# BlueNRG_LP register map
File version: 1.0
CPU: CM0+ r0p0, little endian, no MPU, no FPU, 2 interrupt priority bits
Registers are 32-bit, read-write, reset 0x0 unless marked. A register's access mark holds for its fields unless they carry their own. Offsets are from the block's base; [hi:lo] are bit positions; {n}, {i} and the like mark numbered series.

## ADC
Base 0x41006000
0x00 VERSION_ID ro reset 0x20
  [7:0] VERSION_ID — version of the embedded IP.
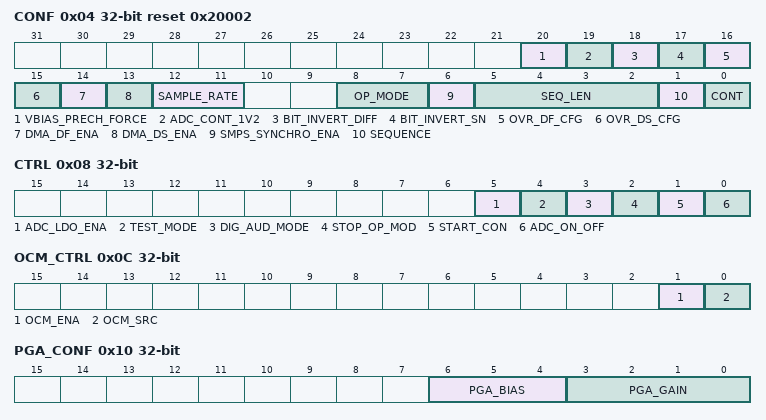
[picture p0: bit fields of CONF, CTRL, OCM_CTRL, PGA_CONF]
0x04 CONF reset 0x20002 — ADC configuration register
  [20] VBIAS_PRECH_FORCE — possibility to keep the VBIAS_PRECH enabled to deactivate the filter
  [19] ADC_CONT_1V2 — select the input sampling method
  [18] BIT_INVERT_DIFF — invert bit to bit the ADC data output when a differential
  [17] BIT_INVERT_SN — invert bit to bit the ADC data output when a single
  [16] OVR_DF_CFG — decimation overrun configuration
  [15] OVR_DS_CFG — Down Sampler overrun configuration
  [14] DMA_DF_ENA — enable DMA mode for Decimation Filter data path
  [13] DMA_DS_ENA — enable DMA mode for Down Sampler data path
  [12:11] SAMPLE_RATE — conversion rate of ADC
  [8:7] OP_MODE — ADC mode selection (= data path selection)
  [6] SMPS_SYNCHRO_ENA — synchronize the ADC start conversion with a pulse generated by the
  [5:2] SEQ_LEN — number of conversions in a regular sequence
  [1] SEQUENCE — enable the sequence mode (active by default)
  [0] CONT — regular sequence runs continuously when ADC mode is enabled
0x08 CTRL — ADC control register
  [5] ADC_LDO_ENA — enable the LDO associated to the ADC block
  [4] TEST_MODE — select the functional or the test mode of the ADC
  [3] DIG_AUD_MODE — enable the digital audio mode (the data path uses the decimation filter)
  [2] STOP_OP_MOD — stop the on-going OP_MODE (ADC mode, Analog audio mode, Full
  [1] START_CON — generate a start pulse to initiate an ADC conversion
  [0] ADC_ON_OFF
0x0C OCM_CTRL — Occasionnal mode control register
  [1] OCM_ENA — start occasional conversion in analog audio and full modes
  [0] OCM_SRC — select the occasional conversion source
0x10 PGA_CONF — PGA configuration register
  [6:4] PGA_BIAS — set the microphone bias voltage
  [3:0] PGA_GAIN — from 6 to 30 dB
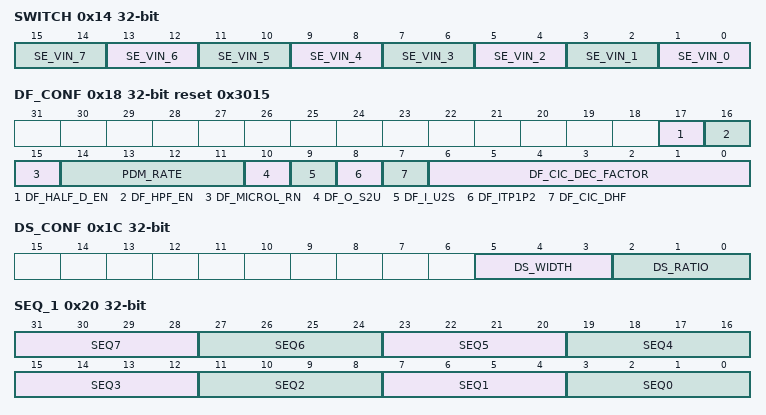
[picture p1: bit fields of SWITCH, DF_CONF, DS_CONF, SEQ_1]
0x14 SWITCH — ADC switch control for Input Selection
  [2n+1:2n] SE_VIN_{n} (n=4..7) — input voltage for VINP[{n-4}]
  [2n+1:2n] SE_VIN_{n} (n=0..3) — input voltage for VINM[{n}] / VINP[{n}]-VINM[{n}]
0x18 DF_CONF reset 0x3015 — Decimation filter configuration register
  [17] DF_HALF_D_EN — half dynamic enable.
  [16] DF_HPF_EN — high pass filter enable.
  [15] DF_MICROL_RN — left/right channel selection on digital microphone
  [14:11] PDM_RATE — select the PDM clock rate.
  [10] DF_O_S2U — select signed/unsigned format for data output
  [9] DF_I_U2S — select signed/unsigned format for input
  [8] DF_ITP1P2 — 1.2 fractional interpolator enable
  [7] DF_CIC_DHF — CIC filter decimator half factor
  [6:0] DF_CIC_DEC_FACTOR
0x1C DS_CONF — Downsampler configuration register
  [5:3] DS_WIDTH — program the Down Sampler width of data output (DSDTATA)
  [2:0] DS_RATIO — program the Down Sampler ratio (N factor)
0x20 SEQ_1 — ADC regular sequence configuration register 1
  [4n+3:4n] SEQ{n} (n=3..7) — channel number code for {n+1}th conversion of the sequence.
  [11:8] SEQ2 — channel number code for 3rd conversion of the sequence.
  [7:4] SEQ1 — channel number code for second conversion of the sequence.
  [3:0] SEQ0 — channel number code for first conversion of the sequence
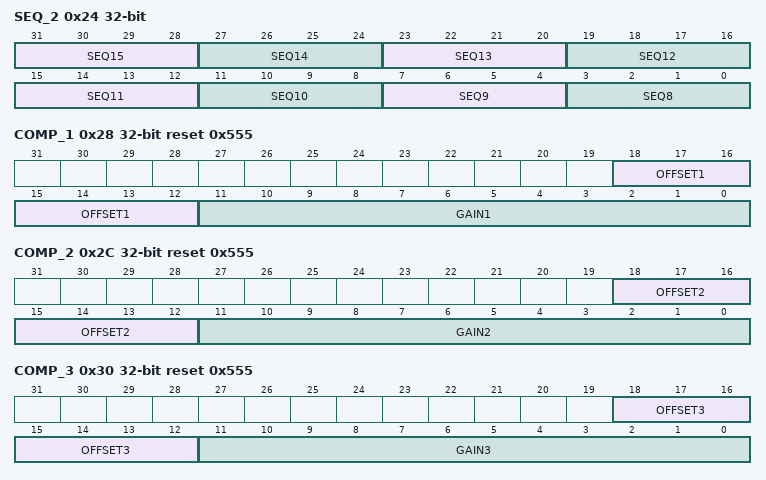
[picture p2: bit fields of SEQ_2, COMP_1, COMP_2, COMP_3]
0x24 SEQ_2 — ADC regular sequence configuration register 2
  [4n-29:4n-32] SEQ{n} (n=9..15) — channel number code for {n+1}th conversion of the sequence.
  [3:0] SEQ8 — channel number code for 9th conversion of the sequence
0x28 COMP_1 reset 0x555 — ADC Gain and offset correction values register 1
  [18:12] OFFSET1 — first calibration point: signed offset compensation[6:0]
  [11:0] GAIN1 — first calibration point: gain AUXADC_GAIN_1V2[11:0]
0x2C COMP_2 reset 0x555 — ADC Gain and offset correction values register 2
  [18:12] OFFSET2 — second calibration point: signed offset compensation[6:0]
  [11:0] GAIN2 — second calibration point: gain AUXADC_GAIN_1V2[11:0]
0x30 COMP_3 reset 0x555 — ADC Gain and offset correction values register 3
  [18:12] OFFSET3 — third calibration point: signed offset compensation[6:0]
  [11:0] GAIN3 — third calibration point: gain AUXADC_GAIN_1V2[11:0]
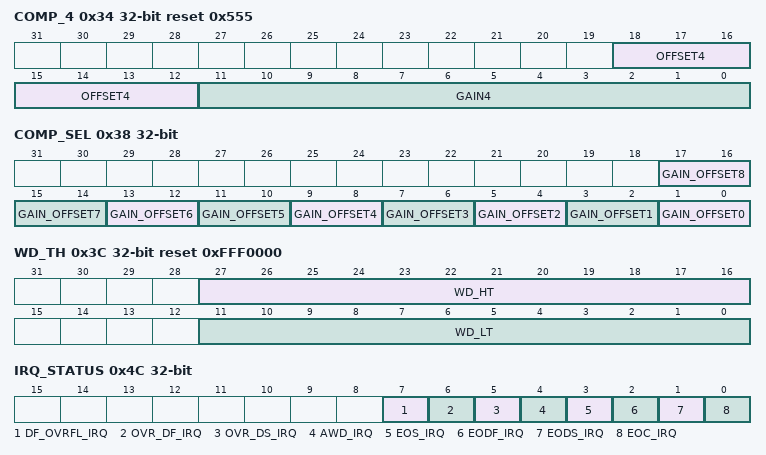
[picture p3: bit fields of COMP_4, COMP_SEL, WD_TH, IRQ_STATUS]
0x34 COMP_4 reset 0x555 — ADC Gain and offset correction values register 4
  [18:12] OFFSET4 — fourth calibration point: signed offset compensation[6:0]
  [11:0] GAIN4 — fourth calibration point: gain AUXADC_GAIN_1V2[11:0]
0x38 COMP_SEL — ADC Gain and Offset selection values register
  [17:16] GAIN_OFFSET8 — gain / offset used in ADC differential mode with Vinput range = 3.6V
  [15:14] GAIN_OFFSET7 — gain / offset used in ADC single positive mode with Vinput range = 3.6V
  [13:12] GAIN_OFFSET6 — gain / offset used in ADC single negative mode with Vinput range = 3.6V
  [11:10] GAIN_OFFSET5 — gain / offset used in ADC differential mode with Vinput range = 2.4V
  [9:8] GAIN_OFFSET4 — gain / offset used in ADC single positive mode with Vinput range = 2.4V
  [7:6] GAIN_OFFSET3 — gain / offset used in ADC single negative mode with Vinput range = 2.4V
  [5:4] GAIN_OFFSET2 — gain / offset used in ADC differential mode with Vinput range = 1.2V
  [3:2] GAIN_OFFSET1 — gain / offset used in ADC single positive mode with Vinput range = 1.2V
  [1:0] GAIN_OFFSET0 — gain / offset used in ADC single negative mode with Vinput range = 1.2V
0x3C WD_TH reset 0xFFF0000 — High/low limits for event monitoring a channel register
  [27:16] WD_HT — analog watchdog high level threshold.
  [11:0] WD_LT — analog watchdog low level threshold.
0x40 WD_CONF — Channel selection for event monitoring register
  [15:0] AWD_CHX — analog watchdog channel selection to define which input channel(s) need to be guarded by the watchdog.
0x44 DS_DATAOUT ro — Downsampler Data output register
  [15:0] DS_DATA — contain the converted data at the output of the Down Sampler.
0x48 DF_DATAOUT ro — Decimation filter Data output register
  [15:0] DF_DATA — contain the converted data at the output of the decimation filter.
0x4C IRQ_STATUS — Interrupt Status register
  [7] DF_OVRFL_IRQ — set to indicate the decimation filter is saturated.
  [6] OVR_DF_IRQ — set to indicate a decimation filter overrun (a data is lost)
  [5] OVR_DS_IRQ — set to indicate a Down Sampler overrun (at least one data is lost)
  [4] AWD_IRQ — set when an analog watchdog event occurs.
  [3] EOS_IRQ — set when a sequence of conversion is completed.
  [2] EODF_IRQ — set when the decimation filter conversion is completed.
  [1] EODS_IRQ — set when the Down Sampler conversion is completed.
  [0] EOC_IRQ — (Used in test mode only): set when the ADC conversion is completed.
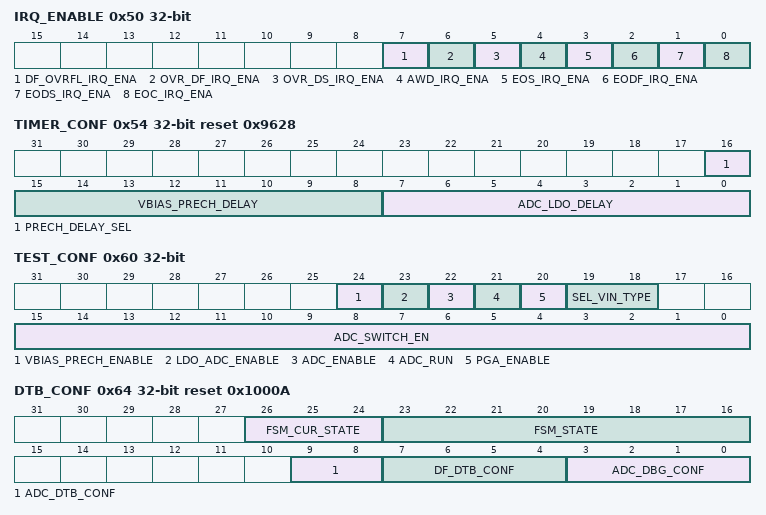
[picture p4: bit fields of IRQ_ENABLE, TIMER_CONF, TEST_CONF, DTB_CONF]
0x50 IRQ_ENABLE — Enable/disable Interrupts
  [7] DF_OVRFL_IRQ_ENA — decimation filter saturation interrupt enable
  [6] OVR_DF_IRQ_ENA — decimation filter overrun interrupt enable
  [5] OVR_DS_IRQ_ENA — Down Sampler overrun interrupt enable
  [4] AWD_IRQ_ENA — analog watchdog interrupt enable
  [3] EOS_IRQ_ENA — End of regular sequence interrupt enable
  [2] EODF_IRQ_ENA — End of conversion interrupt enable for the decimation filter output
  [1] EODS_IRQ_ENA — End of conversion interrupt enable for the Down Sampler output
  [0] EOC_IRQ_ENA — (Used in test mode only): End of ADC conversion interrupt enable
0x54 TIMER_CONF reset 0x9628 — Time to add after an LDO Enable or ADC Enable to let the HW to be stable before using it
  [16] PRECH_DELAY_SEL — Select the time step PD_STEP for the VBIAS_PRECH_DELAY timer.
  [15:8] VBIAS_PRECH_DELAY — define the duration of a waiting time starting at rising edge of PGA_EN signal and corresponding to the VBIAS precharge duration.
  [7:0] ADC_LDO_DELAY — define the duration of a waiting time to be inserted between the ADC_LDO enable and the ADC ON to let time to the LDO to stabilize before starting a conversion.
0x60 TEST_CONF
  [24] VBIAS_PRECH_ENABLE — set and reset by the software, knowing the bit must stay high at
  [23] LDO_ADC_ENABLE
  [22] ADC_ENABLE
  [21] ADC_RUN — Start/stop ADC conversion.
  [20] PGA_ENABLE
  [19:18] SEL_VIN_TYPE — operation mode of the selected VIN
  [15:0] ADC_SWITCH_EN — enable individually each connection of the switching matrix at the ADC input, corresponding to AUXADC_INSEL_1V2[15:0].
0x64 DTB_CONF reset 0x1000A
  [26:24] FSM_CUR_STATE — show the last executed state by the state machine.
  [23:16] FSM_STATE — show the state of the state machine.
  [9:8] ADC_DTB_CONF — configure the DTB output.
  [7:4] DF_DTB_CONF — internal decimation filter multiplexing.
  [3:0] ADC_DBG_CONF — use for debug purpose.
